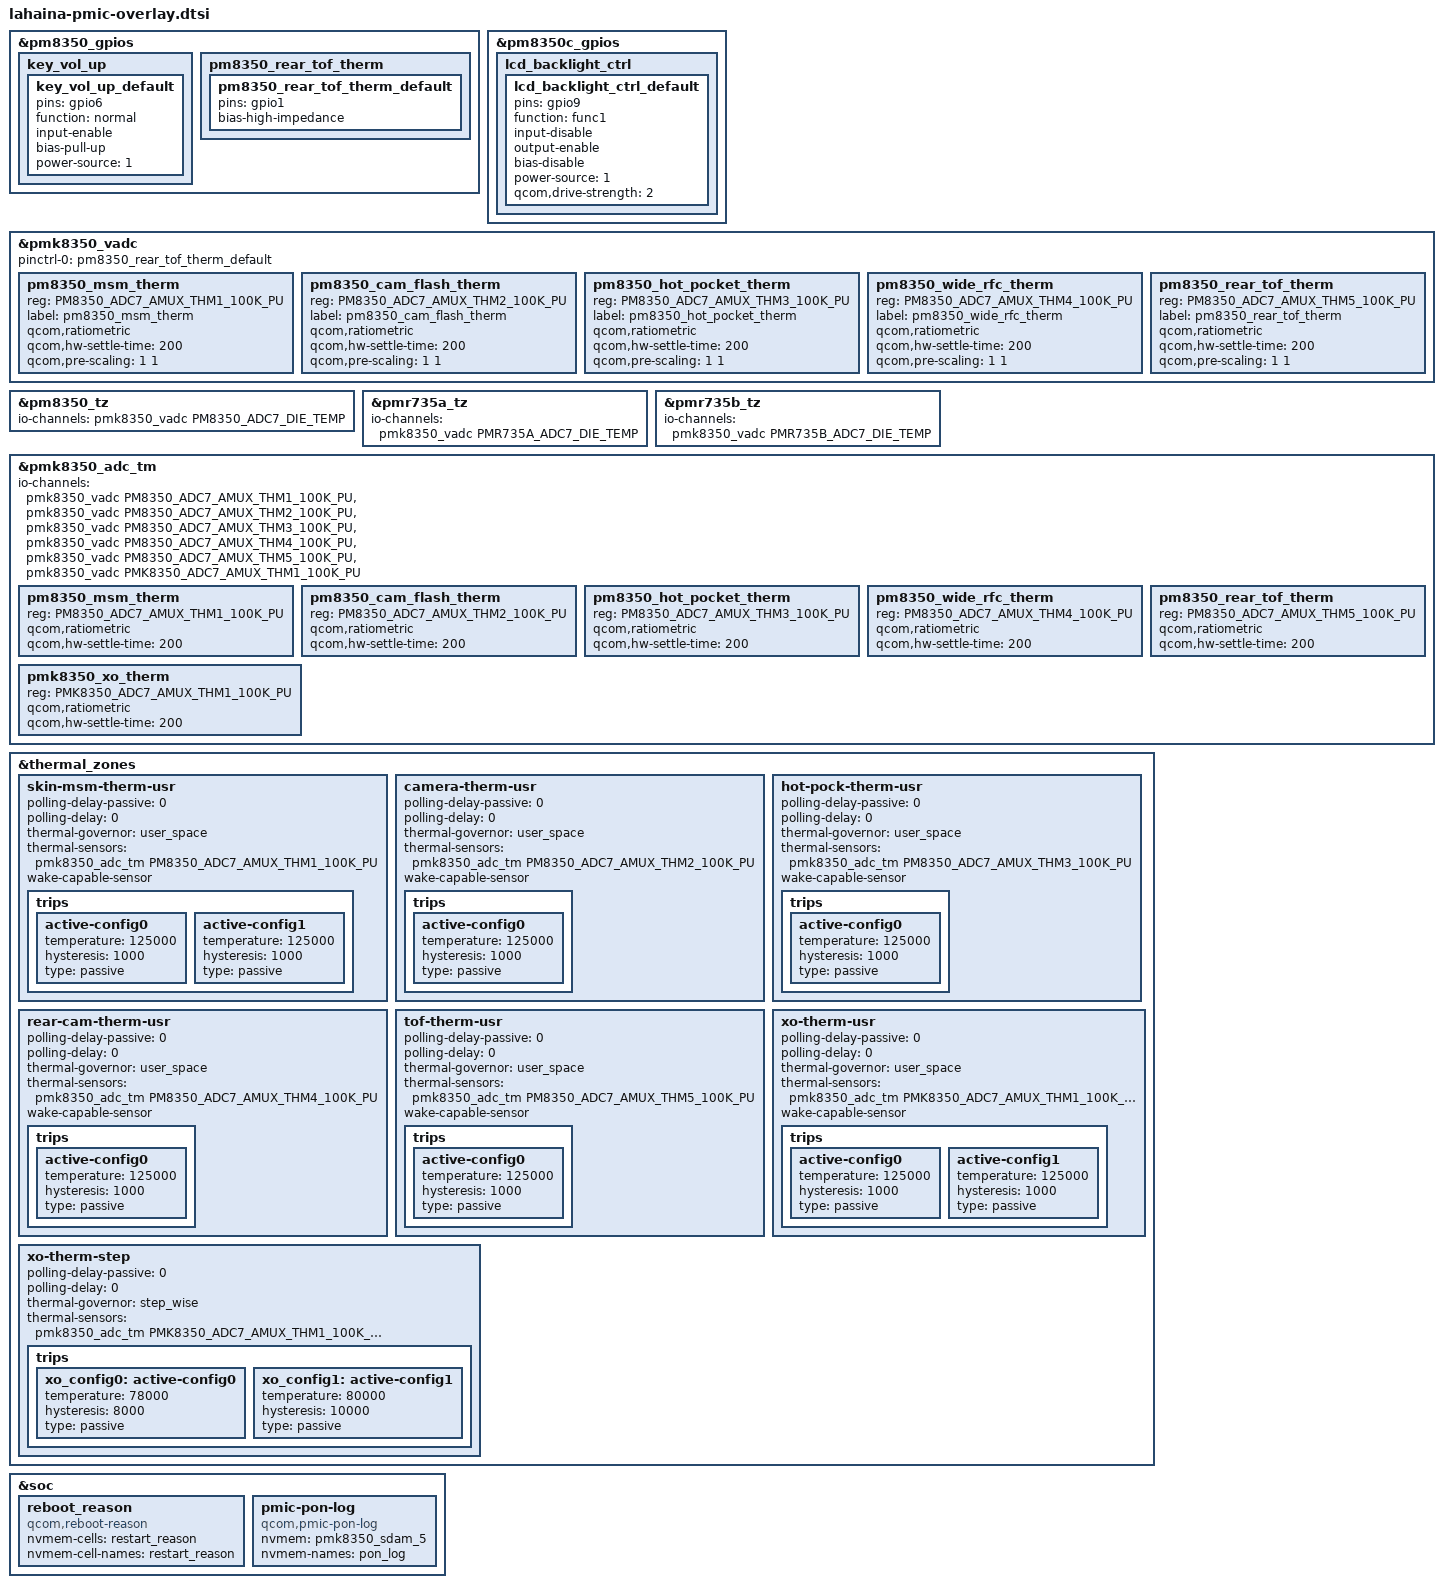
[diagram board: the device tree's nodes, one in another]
#include <dt-bindings/pinctrl/qcom,pmic-gpio.h>

#include "pmk8350.dtsi"
#include "pm8350.dtsi"
#include "pm8350c.dtsi"
#include "pmr735a.dtsi"
#include "pmr735b.dtsi"

&pm8350_gpios {
	key_vol_up {
		key_vol_up_default: key_vol_up_default {
			pins = "gpio6";
			function = "normal";
			input-enable;
			bias-pull-up;
			power-source = <1>;
		};
	};
};

&pm8350c_gpios {
	lcd_backlight_ctrl {
		lcd_backlight_ctrl_default: lcd_backlight_ctrl_default {
			pins = "gpio9";
			function = "func1";
			input-disable;
			output-enable;
			bias-disable;
			power-source = <1>;	/* 1.8V */
			qcom,drive-strength = <2>;
		};
	};
};

&pm8350_gpios {
	pm8350_rear_tof_therm {
		pm8350_rear_tof_therm_default: pm8350_rear_tof_therm_default {
			pins = "gpio1";
			bias-high-impedance;
		};
	};
};

&pmk8350_vadc {
	pinctrl-names = "default";
	pinctrl-0 = <&pm8350_rear_tof_therm_default>;

	pm8350_msm_therm {
		reg = <PM8350_ADC7_AMUX_THM1_100K_PU>;
		label = "pm8350_msm_therm";
		qcom,ratiometric;
		qcom,hw-settle-time = <200>;
		qcom,pre-scaling = <1 1>;
	};

	pm8350_cam_flash_therm {
		reg = <PM8350_ADC7_AMUX_THM2_100K_PU>;
		label = "pm8350_cam_flash_therm";
		qcom,ratiometric;
		qcom,hw-settle-time = <200>;
		qcom,pre-scaling = <1 1>;
	};

	pm8350_hot_pocket_therm {
		reg = <PM8350_ADC7_AMUX_THM3_100K_PU>;
		label = "pm8350_hot_pocket_therm";
		qcom,ratiometric;
		qcom,hw-settle-time = <200>;
		qcom,pre-scaling = <1 1>;
	};

	pm8350_wide_rfc_therm {
		reg = <PM8350_ADC7_AMUX_THM4_100K_PU>;
		label = "pm8350_wide_rfc_therm";
		qcom,ratiometric;
		qcom,hw-settle-time = <200>;
		qcom,pre-scaling = <1 1>;
	};

	pm8350_rear_tof_therm {
		reg = <PM8350_ADC7_AMUX_THM5_100K_PU>;
		label = "pm8350_rear_tof_therm";
		qcom,ratiometric;
		qcom,hw-settle-time = <200>;
		qcom,pre-scaling = <1 1>;
	};
};

&pm8350_tz {
	io-channels = <&pmk8350_vadc PM8350_ADC7_DIE_TEMP>;
	io-channel-names = "thermal";
};

&pmr735a_tz {
	io-channels = <&pmk8350_vadc PMR735A_ADC7_DIE_TEMP>;
	io-channel-names = "thermal";
};

&pmr735b_tz {
	io-channels = <&pmk8350_vadc PMR735B_ADC7_DIE_TEMP>;
	io-channel-names = "thermal";
};

&pmk8350_adc_tm {
	io-channels = <&pmk8350_vadc PM8350_ADC7_AMUX_THM1_100K_PU>,
			<&pmk8350_vadc PM8350_ADC7_AMUX_THM2_100K_PU>,
			<&pmk8350_vadc PM8350_ADC7_AMUX_THM3_100K_PU>,
			<&pmk8350_vadc PM8350_ADC7_AMUX_THM4_100K_PU>,
			<&pmk8350_vadc PM8350_ADC7_AMUX_THM5_100K_PU>,
			<&pmk8350_vadc PMK8350_ADC7_AMUX_THM1_100K_PU>;

	pm8350_msm_therm {
		reg = <PM8350_ADC7_AMUX_THM1_100K_PU>;
		qcom,ratiometric;
		qcom,hw-settle-time = <200>;
	};

	pm8350_cam_flash_therm {
		reg = <PM8350_ADC7_AMUX_THM2_100K_PU>;
		qcom,ratiometric;
		qcom,hw-settle-time = <200>;
	};

	pm8350_hot_pocket_therm {
		reg = <PM8350_ADC7_AMUX_THM3_100K_PU>;
		qcom,ratiometric;
		qcom,hw-settle-time = <200>;
	};

	pm8350_wide_rfc_therm {
		reg = <PM8350_ADC7_AMUX_THM4_100K_PU>;
		qcom,ratiometric;
		qcom,hw-settle-time = <200>;
	};

	pm8350_rear_tof_therm {
		reg = <PM8350_ADC7_AMUX_THM5_100K_PU>;
		qcom,ratiometric;
		qcom,hw-settle-time = <200>;
	};

	pmk8350_xo_therm {
		reg = <PMK8350_ADC7_AMUX_THM1_100K_PU>;
		qcom,ratiometric;
		qcom,hw-settle-time = <200>;
	};
};

&thermal_zones {
	skin-msm-therm-usr {
		polling-delay-passive = <0>;
		polling-delay = <0>;
		thermal-governor = "user_space";
		thermal-sensors = <&pmk8350_adc_tm PM8350_ADC7_AMUX_THM1_100K_PU>;
		wake-capable-sensor;
		trips {
			active-config0 {
				temperature = <125000>;
				hysteresis = <1000>;
				type = "passive";
			};

			active-config1 {
				temperature = <125000>;
				hysteresis = <1000>;
				type = "passive";
			};
		};
	};

	camera-therm-usr {
		polling-delay-passive = <0>;
		polling-delay = <0>;
		thermal-governor = "user_space";
		thermal-sensors = <&pmk8350_adc_tm PM8350_ADC7_AMUX_THM2_100K_PU>;
		wake-capable-sensor;
		trips {
			active-config0 {
				temperature = <125000>;
				hysteresis = <1000>;
				type = "passive";
			};
		};
	};

	hot-pock-therm-usr {
		polling-delay-passive = <0>;
		polling-delay = <0>;
		thermal-governor = "user_space";
		thermal-sensors = <&pmk8350_adc_tm PM8350_ADC7_AMUX_THM3_100K_PU>;
		wake-capable-sensor;
		trips {
			active-config0 {
				temperature = <125000>;
				hysteresis = <1000>;
				type = "passive";
			};
		};
	};

	rear-cam-therm-usr {
		polling-delay-passive = <0>;
		polling-delay = <0>;
		thermal-governor = "user_space";
		thermal-sensors = <&pmk8350_adc_tm PM8350_ADC7_AMUX_THM4_100K_PU>;
		wake-capable-sensor;
		trips {
			active-config0 {
				temperature = <125000>;
				hysteresis = <1000>;
				type = "passive";
			};
		};
	};

	tof-therm-usr {
		polling-delay-passive = <0>;
		polling-delay = <0>;
		thermal-governor = "user_space";
		thermal-sensors = <&pmk8350_adc_tm PM8350_ADC7_AMUX_THM5_100K_PU>;
		wake-capable-sensor;
		trips {
			active-config0 {
				temperature = <125000>;
				hysteresis = <1000>;
				type = "passive";
			};
		};
	};

	xo-therm-usr {
		polling-delay-passive = <0>;
		polling-delay = <0>;
		thermal-governor = "user_space";
		thermal-sensors = <&pmk8350_adc_tm PMK8350_ADC7_AMUX_THM1_100K_PU>;
		wake-capable-sensor;
		trips {
			active-config0 {
				temperature = <125000>;
				hysteresis = <1000>;
				type = "passive";
			};

			active-config1 {
				temperature = <125000>;
				hysteresis = <1000>;
				type = "passive";
			};
		};
	};

	xo-therm-step {
		polling-delay-passive = <0>;
		polling-delay = <0>;
		thermal-governor = "step_wise";
		thermal-sensors = <&pmk8350_adc_tm PMK8350_ADC7_AMUX_THM1_100K_PU>;

		trips {
			xo_config0: active-config0 {
				temperature = <78000>;
				hysteresis = <8000>;
				type = "passive";
			};

			xo_config1: active-config1 {
				temperature = <80000>;
				hysteresis = <10000>;
				type = "passive";
			};
		};
	};
};

&soc {
	reboot_reason: reboot_reason {
		compatible = "qcom,reboot-reason";
		nvmem-cells = <&restart_reason>;
		nvmem-cell-names = "restart_reason";
	};
};

&soc {
	pmic-pon-log {
		compatible = "qcom,pmic-pon-log";
		nvmem = <&pmk8350_sdam_5>;
		nvmem-names = "pon_log";
	};
};
